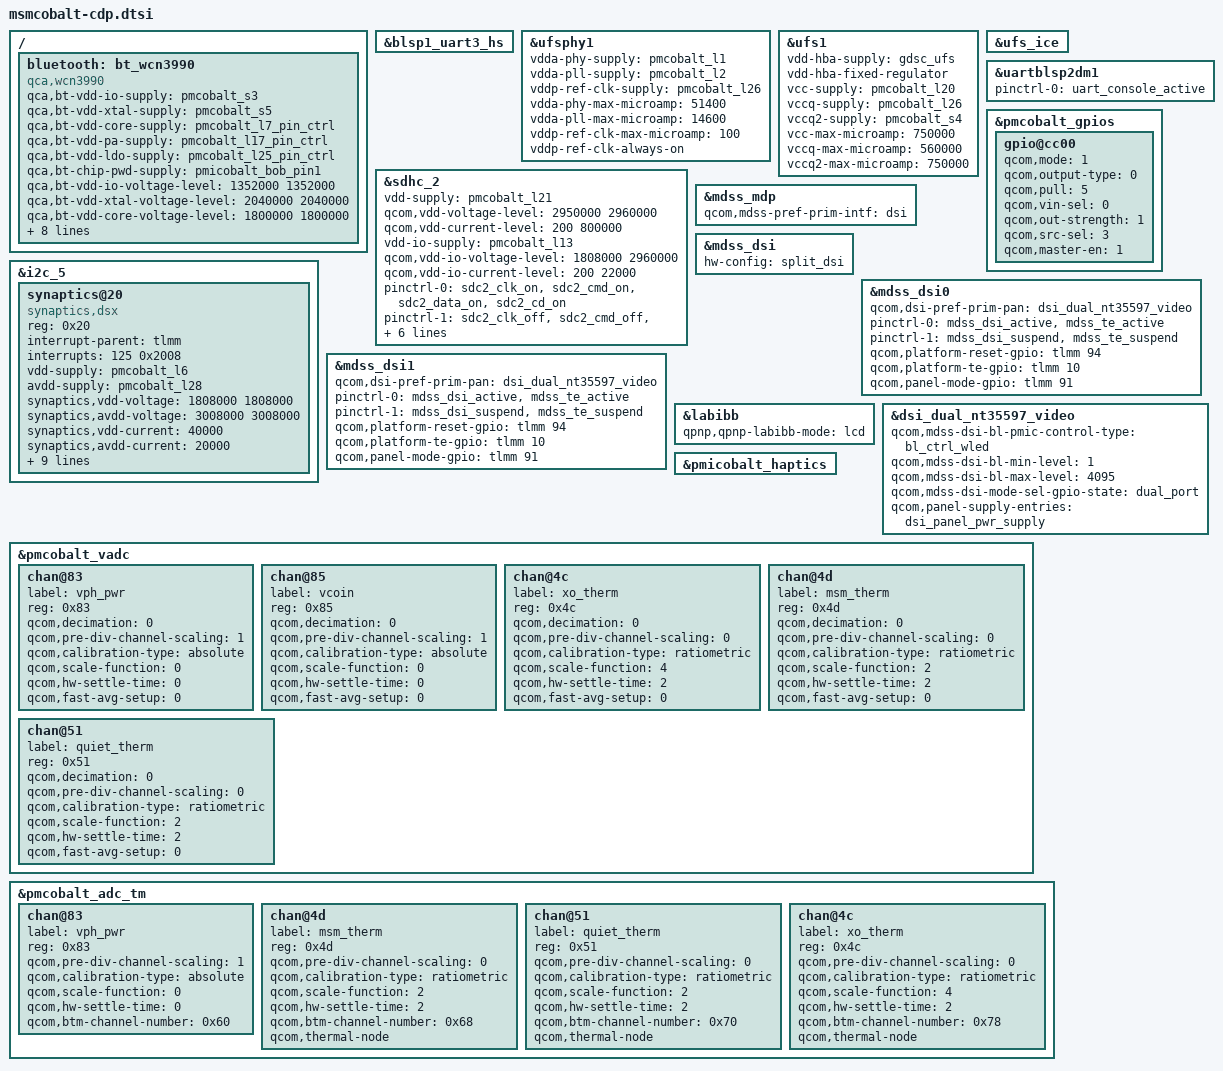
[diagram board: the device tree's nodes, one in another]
/* Copyright (c) 2016, The Linux Foundation. All rights reserved.
 *
 * This program is free software; you can redistribute it and/or modify
 * it under the terms of the GNU General Public License version 2 and
 * only version 2 as published by the Free Software Foundation.
 *
 * This program is distributed in the hope that it will be useful,
 * but WITHOUT ANY WARRANTY; without even the implied warranty of
 * MERCHANTABILITY or FITNESS FOR A PARTICULAR PURPOSE.  See the
 * GNU General Public License for more details.
 */

#include "msmcobalt-pinctrl.dtsi"
#include "msmcobalt-camera-sensor-cdp.dtsi"
/ {
	bluetooth: bt_wcn3990 {
		compatible = "qca,wcn3990";
		qca,bt-vdd-io-supply = <&pmcobalt_s3>;
		qca,bt-vdd-xtal-supply = <&pmcobalt_s5>;
		qca,bt-vdd-core-supply = <&pmcobalt_l7_pin_ctrl>;
		qca,bt-vdd-pa-supply = <&pmcobalt_l17_pin_ctrl>;
		qca,bt-vdd-ldo-supply = <&pmcobalt_l25_pin_ctrl>;
		qca,bt-chip-pwd-supply = <&pmicobalt_bob_pin1>;

		qca,bt-vdd-io-voltage-level = <1352000 1352000>;
		qca,bt-vdd-xtal-voltage-level = <2040000 2040000>;
		qca,bt-vdd-core-voltage-level = <1800000 1800000>;
		qca,bt-vdd-pa-voltage-level = <1304000 1304000>;
		qca,bt-vdd-ldo-voltage-level = <3312000 3312000>;
		qca,bt-chip-pwd-voltage-level = <3600000 3600000>;

		qca,bt-vdd-io-current-level = <1>; /* LPM/PFM */
		qca,bt-vdd-xtal-current-level = <1>; /* LPM/PFM */
		qca,bt-vdd-core-current-level = <0>; /* LPM/PFM */
		qca,bt-vdd-pa-current-level = <0>; /* LPM/PFM */
		qca,bt-vdd-ldo-current-level = <0>; /* LPM/PFM */
	};
};

&blsp1_uart3_hs {
	status = "ok";
};

&ufsphy1 {
	vdda-phy-supply = <&pmcobalt_l1>;
	vdda-pll-supply = <&pmcobalt_l2>;
	vddp-ref-clk-supply = <&pmcobalt_l26>;
	vdda-phy-max-microamp = <51400>;
	vdda-pll-max-microamp = <14600>;
	vddp-ref-clk-max-microamp = <100>;
	vddp-ref-clk-always-on;
	status = "ok";
};

&ufs1 {
	vdd-hba-supply = <&gdsc_ufs>;
	vdd-hba-fixed-regulator;
	vcc-supply = <&pmcobalt_l20>;
	vccq-supply = <&pmcobalt_l26>;
	vccq2-supply = <&pmcobalt_s4>;
	vcc-max-microamp = <750000>;
	vccq-max-microamp = <560000>;
	vccq2-max-microamp = <750000>;
	status = "ok";
};

&ufs_ice {
	status = "ok";
};

&sdhc_2 {
	vdd-supply = <&pmcobalt_l21>;
	qcom,vdd-voltage-level = <2950000 2960000>;
	qcom,vdd-current-level = <200 800000>;

	vdd-io-supply = <&pmcobalt_l13>;
	qcom,vdd-io-voltage-level = <1808000 2960000>;
	qcom,vdd-io-current-level = <200 22000>;

	pinctrl-names = "active", "sleep";
	pinctrl-0 = <&sdc2_clk_on  &sdc2_cmd_on &sdc2_data_on &sdc2_cd_on>;
	pinctrl-1 = <&sdc2_clk_off &sdc2_cmd_off &sdc2_data_off &sdc2_cd_off>;

	qcom,clk-rates = <400000 20000000 25000000
				50000000 100000000 200000000>;
	qcom,bus-speed-mode = "SDR12", "SDR25", "SDR50", "DDR50", "SDR104";

	cd-gpios = <&tlmm 95 0x1>;

	status = "ok";
};

&uartblsp2dm1 {
	status = "ok";
	pinctrl-names = "default";
	pinctrl-0 = <&uart_console_active>;
};

&pmcobalt_gpios {
	gpio@cc00 { /* GPIO 13 */
		qcom,mode = <1>;
		qcom,output-type = <0>;
		qcom,pull = <5>;
		qcom,vin-sel = <0>;
		qcom,out-strength = <1>;
		qcom,src-sel = <3>;
		qcom,master-en = <1>;
		status = "okay";
	};
};

&i2c_5 {
	status = "okay";
	synaptics@20 {
		compatible = "synaptics,dsx";
		reg = <0x20>;
		interrupt-parent = <&tlmm>;
		interrupts = <125 0x2008>;
		vdd-supply = <&pmcobalt_l6>;
		avdd-supply = <&pmcobalt_l28>;
		synaptics,vdd-voltage = <1808000 1808000>;
		synaptics,avdd-voltage = <3008000 3008000>;
		synaptics,vdd-current = <40000>;
		synaptics,avdd-current = <20000>;
		pinctrl-names = "pmx_ts_active", "pmx_ts_suspend";
		pinctrl-0 = <&ts_active>;
		pinctrl-1 = <&ts_suspend>;
		synaptics,display-coords = <0 0 1439 2559>;
		synaptics,panel-coords = <0 0 1439 2559>;
		synaptics,reset-gpio = <&tlmm 89 0x00>;
		synaptics,irq-gpio = <&tlmm 125 0x2008>;
		synaptics,disable-gpios;
		synaptics,fw-name = "PR1702898-s3528t_60QHD_00400001.img";
	};
};

&mdss_mdp {
	qcom,mdss-pref-prim-intf = "dsi";
};

&mdss_dsi {
	hw-config = "split_dsi";
};

&mdss_dsi0 {
	qcom,dsi-pref-prim-pan = <&dsi_dual_nt35597_video>;
	pinctrl-names = "mdss_default", "mdss_sleep";
	pinctrl-0 = <&mdss_dsi_active &mdss_te_active>;
	pinctrl-1 = <&mdss_dsi_suspend &mdss_te_suspend>;
	qcom,platform-reset-gpio = <&tlmm 94 0>;
	qcom,platform-te-gpio = <&tlmm 10 0>;
	qcom,panel-mode-gpio = <&tlmm 91 0>;
};

&mdss_dsi1 {
	qcom,dsi-pref-prim-pan = <&dsi_dual_nt35597_video>;
	pinctrl-names = "mdss_default", "mdss_sleep";
	pinctrl-0 = <&mdss_dsi_active &mdss_te_active>;
	pinctrl-1 = <&mdss_dsi_suspend &mdss_te_suspend>;
	qcom,platform-reset-gpio = <&tlmm 94 0>;
	qcom,platform-te-gpio = <&tlmm 10 0>;
	qcom,panel-mode-gpio = <&tlmm 91 0>;
};

&labibb {
	status = "ok";
	qpnp,qpnp-labibb-mode = "lcd";
};

&dsi_dual_nt35597_video {
	qcom,mdss-dsi-bl-pmic-control-type = "bl_ctrl_wled";
	qcom,mdss-dsi-bl-min-level = <1>;
	qcom,mdss-dsi-bl-max-level = <4095>;
	qcom,mdss-dsi-mode-sel-gpio-state = "dual_port";
	qcom,panel-supply-entries = <&dsi_panel_pwr_supply>;
};

&pmicobalt_haptics {
	status = "okay";
};

&pmcobalt_vadc {
	chan@83 {
		label = "vph_pwr";
		reg = <0x83>;
		qcom,decimation = <0>;
		qcom,pre-div-channel-scaling = <1>;
		qcom,calibration-type = "absolute";
		qcom,scale-function = <0>;
		qcom,hw-settle-time = <0>;
		qcom,fast-avg-setup = <0>;
	};

	chan@85 {
		label = "vcoin";
		reg = <0x85>;
		qcom,decimation = <0>;
		qcom,pre-div-channel-scaling = <1>;
		qcom,calibration-type = "absolute";
		qcom,scale-function = <0>;
		qcom,hw-settle-time = <0>;
		qcom,fast-avg-setup = <0>;
	};

	chan@4c {
		label = "xo_therm";
		reg = <0x4c>;
		qcom,decimation = <0>;
		qcom,pre-div-channel-scaling = <0>;
		qcom,calibration-type = "ratiometric";
		qcom,scale-function = <4>;
		qcom,hw-settle-time = <2>;
		qcom,fast-avg-setup = <0>;
	};

	chan@4d {
		label = "msm_therm";
		reg = <0x4d>;
		qcom,decimation = <0>;
		qcom,pre-div-channel-scaling = <0>;
		qcom,calibration-type = "ratiometric";
		qcom,scale-function = <2>;
		qcom,hw-settle-time = <2>;
		qcom,fast-avg-setup = <0>;
	};

	chan@51 {
		label = "quiet_therm";
		reg = <0x51>;
		qcom,decimation = <0>;
		qcom,pre-div-channel-scaling = <0>;
		qcom,calibration-type = "ratiometric";
		qcom,scale-function = <2>;
		qcom,hw-settle-time = <2>;
		qcom,fast-avg-setup = <0>;
	};
};

&pmcobalt_adc_tm {
	chan@83 {
		label = "vph_pwr";
		reg = <0x83>;
		qcom,pre-div-channel-scaling = <1>;
		qcom,calibration-type = "absolute";
		qcom,scale-function = <0>;
		qcom,hw-settle-time = <0>;
		qcom,btm-channel-number = <0x60>;
	};

	chan@4d {
		label = "msm_therm";
		reg = <0x4d>;
		qcom,pre-div-channel-scaling = <0>;
		qcom,calibration-type = "ratiometric";
		qcom,scale-function = <2>;
		qcom,hw-settle-time = <2>;
		qcom,btm-channel-number = <0x68>;
		qcom,thermal-node;
	};

	chan@51 {
		label = "quiet_therm";
		reg = <0x51>;
		qcom,pre-div-channel-scaling = <0>;
		qcom,calibration-type = "ratiometric";
		qcom,scale-function = <2>;
		qcom,hw-settle-time = <2>;
		qcom,btm-channel-number = <0x70>;
		qcom,thermal-node;
	};

	chan@4c {
		label = "xo_therm";
		reg = <0x4c>;
		qcom,pre-div-channel-scaling = <0>;
		qcom,calibration-type = "ratiometric";
		qcom,scale-function = <4>;
		qcom,hw-settle-time = <2>;
		qcom,btm-channel-number = <0x78>;
		qcom,thermal-node;
	};
};
